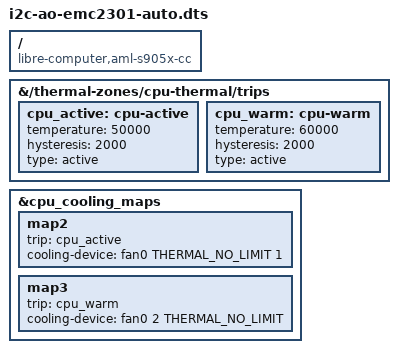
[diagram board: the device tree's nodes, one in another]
// SPDX-License-Identifier: (GPL-2.0-or-later OR MIT)
/*
 * Copyright (C) 2025 Da Xue
 * Author: Da Xue <da@libre.computer>
 */
/*
 * Summary: Temperature-based fan control for EMC2301 on I2C_AO (LoveRPi PoE HAT)
 *
 * Pins (Header.Pin  Name  Pad  Ref — cross-ref gpio.map):
 *   7J1.3    GPIOAO_5      D13     I2C_SDA_AO
 *   7J1.5    GPIOAO_4      A10     I2C_SCK_AO
 *
 * Requires: i2c-ao-emc2301
 * Resource-requires: emc2301-fan
 *
 * Notes:
 *   Maps cpu-thermal trips to fan0 from i2c-ao-emc2301. Enable bus + device
 *   first (i2c-ao, i2c-ao-emc2301) or let ldto expand dt.deps.
 */

/dts-v1/;
/plugin/;

#include <dt-bindings/thermal/thermal.h>

/ {
	compatible = "libre-computer,aml-s905x-cc",
		     "libretech,aml-s905x-cc",
		     "libre-computer,aml-s905x-cc-v2",
		     "libretech,aml-s905x-cc-v2",
		"libre-computer,aml-s905x-cc-v3",
		"libretech,aml-s905x-cc-v3",
		     "amlogic,s905x",
		     "amlogic,meson-gxl";
fragment@0 {
		target-path = "/thermal-zones/cpu-thermal/trips";

		__overlay__ {
			cpu_active: cpu-active {
				temperature = <50000>;
				hysteresis = <2000>;
				type = "active";
			};
			cpu_warm: cpu-warm {
				temperature = <60000>;
				hysteresis = <2000>;
				type = "active";
			};
		};
	};

	fragment@1 {
		target = <&cpu_cooling_maps>;

		__overlay__ {
			map2 {
				trip = <&cpu_active>;
				cooling-device = <&fan0 THERMAL_NO_LIMIT 1>;
			};
			map3 {
				trip = <&cpu_warm>;
				cooling-device = <&fan0 2 THERMAL_NO_LIMIT>;
			};
		};
	};
};
